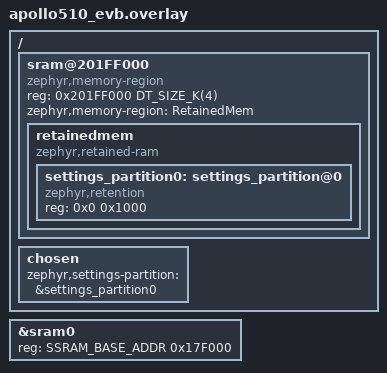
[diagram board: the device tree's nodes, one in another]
/ {
	sram@201FF000 {
		compatible = "zephyr,memory-region", "mmio-sram";
		reg = <0x201FF000 DT_SIZE_K(4)>;
		zephyr,memory-region = "RetainedMem";
		status = "okay";

		retainedmem {
			compatible = "zephyr,retained-ram";
			status = "okay";
			#address-cells = <1>;
			#size-cells = <1>;

			settings_partition0: settings_partition@0 {
				compatible = "zephyr,retention";
				status = "okay";
				reg = <0x0 0x1000>;
			};
		};
	};

	chosen {
		zephyr,settings-partition = &settings_partition0;
	};
};

&sram0 {
	reg = <SSRAM_BASE_ADDR 0x17F000>;
};
